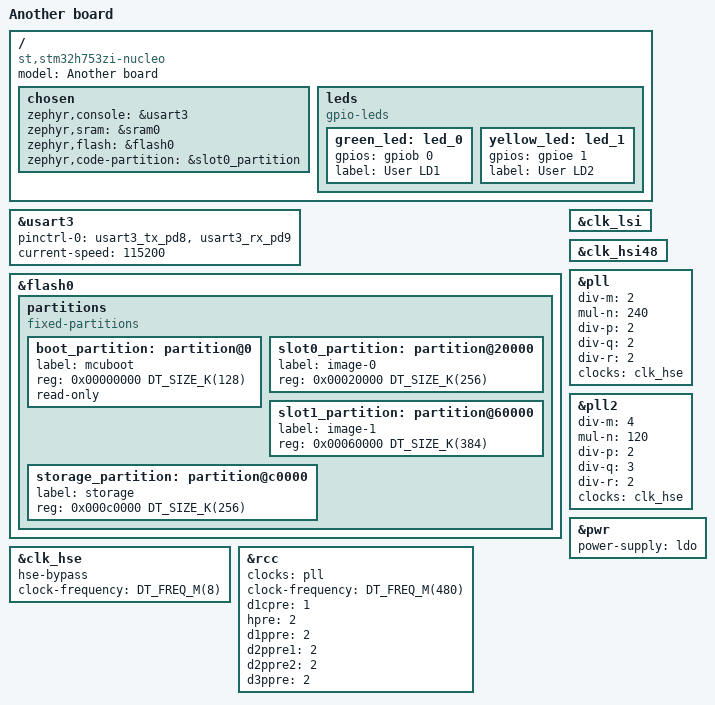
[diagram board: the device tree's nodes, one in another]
/dts-v1/;
#include <st/h7/stm32h753Xi.dtsi>
#include <st/h7/stm32h753zitx-pinctrl.dtsi>

/{
	model = "Another board";
	compatible = "st,stm32h753zi-nucleo";

	chosen {
		zephyr,console = &usart3;
		zephyr,sram = &sram0;
		zephyr,flash = &flash0;
		zephyr,code-partition = &slot0_partition;
	};

	leds: leds {
		compatible = "gpio-leds";

		green_led: led_0 {
			gpios = <&gpiob 0 GPIO_ACTIVE_HIGH>;
			label = "User LD1";
		};

		yellow_led: led_1 {
			gpios = <&gpioe 1 GPIO_ACTIVE_HIGH>;
			label = "User LD2";
		};
	};
};

&usart3 {
	pinctrl-0 = <&usart3_tx_pd8 &usart3_rx_pd9>;
	pinctrl-names = "default";
	current-speed = <115200>;
	status = "okay";
};

&flash0 {
	partitions {
		compatible = "fixed-partitions";
		#address-cells = <1>;
		#size-cells = <1>;

		/* 128KB for bootloader */
		boot_partition: partition@0 {
			label = "mcuboot";
			reg = <0x00000000 DT_SIZE_K(128)>;
			read-only;
		};

		/* application image slot: 256KB */
		slot0_partition: partition@20000 {
			label = "image-0";
			reg = <0x00020000 DT_SIZE_K(256)>;
		};

		/* backup slot: 384KB */
		slot1_partition: partition@60000 {
			label = "image-1";
			reg = <0x00060000 DT_SIZE_K(384)>;
		};

		/* storage: 256KB for settings */
		storage_partition: partition@c0000 {
			label = "storage";
			reg = <0x000c0000 DT_SIZE_K(256)>;
		};
	};
};

&clk_lsi {
	status = "okay";
};

&clk_hsi48 {
	status = "okay";
};

&clk_hse {
	hse-bypass;
	clock-frequency = <DT_FREQ_M(8)>; /* STLink 8MHz clock */
	status = "okay";
};

&pll {
	div-m = <2>;
	mul-n = <240>;
	div-p = <2>;
	div-q = <2>;
	div-r = <2>;
	clocks = <&clk_hse>;
	status = "okay";
};

&pll2 {
	div-m = <4>;
	mul-n = <120>;
	div-p = <2>;
	div-q = <3>; /* gives 80MHz to the FDCAN */
	div-r = <2>;
	clocks = <&clk_hse>;
	status = "okay";
};

&rcc {
	clocks = <&pll>;
	clock-frequency = <DT_FREQ_M(480)>;
	d1cpre = <1>;
	hpre = <2>;
	d1ppre = <2>;
	d2ppre1 = <2>;
	d2ppre2 = <2>;
	d3ppre = <2>;
};

&pwr {
	power-supply = "ldo";
};
